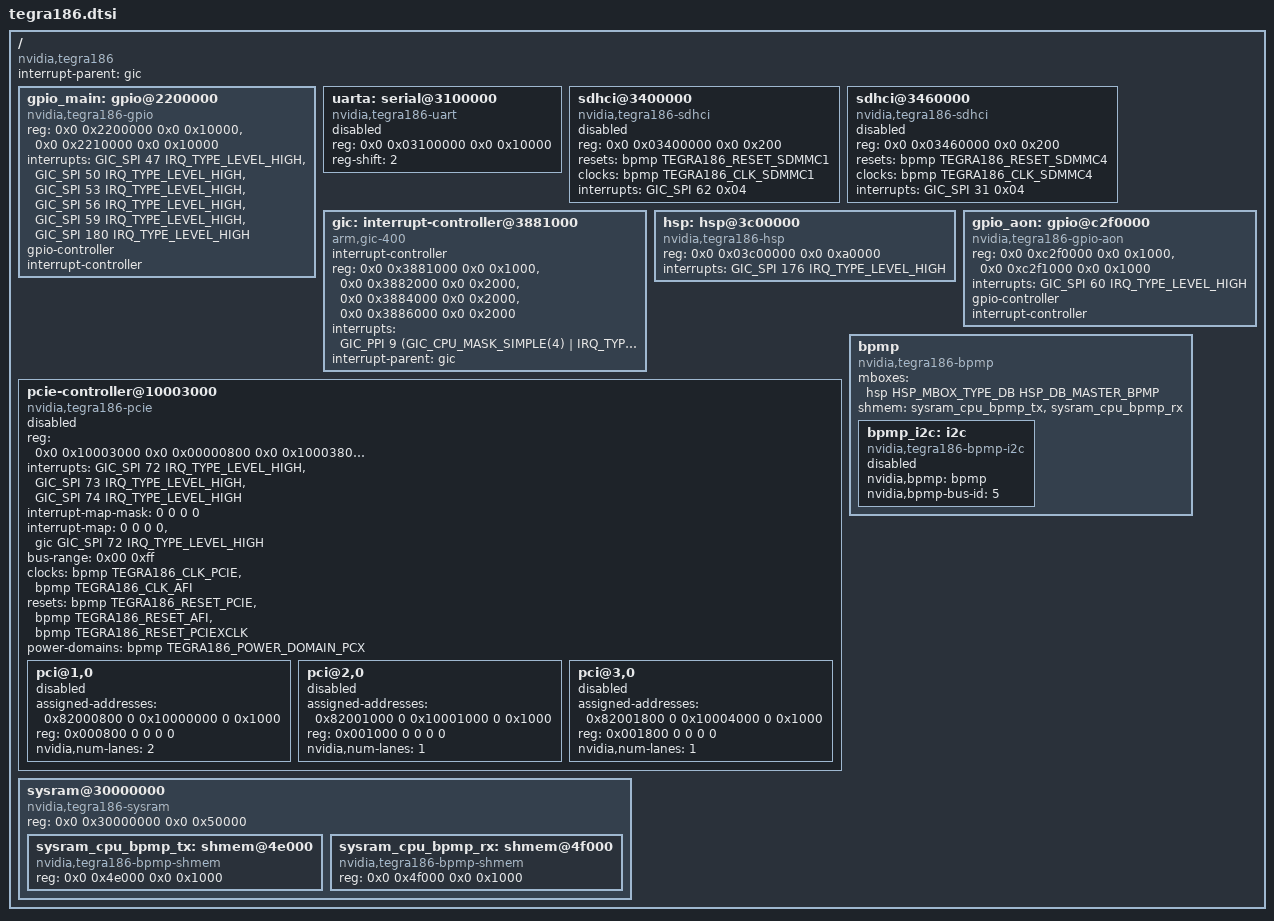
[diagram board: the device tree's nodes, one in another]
#include "skeleton.dtsi"
#include <dt-bindings/clock/tegra186-clock.h>
#include <dt-bindings/gpio/tegra186-gpio.h>
#include <dt-bindings/interrupt-controller/arm-gic.h>
#include <dt-bindings/mailbox/tegra186-hsp.h>
#include <dt-bindings/power/tegra186-powergate.h>
#include <dt-bindings/reset/tegra186-reset.h>

/ {
	compatible = "nvidia,tegra186";
	interrupt-parent = <&gic>;
	#address-cells = <2>;
	#size-cells = <2>;

	gpio_main: gpio@2200000 {
		compatible = "nvidia,tegra186-gpio";
		reg-names = "security", "gpio";
		reg =
			<0x0 0x2200000 0x0 0x10000>,
			<0x0 0x2210000 0x0 0x10000>;
		interrupts =
			<GIC_SPI 47 IRQ_TYPE_LEVEL_HIGH>,
			<GIC_SPI 50 IRQ_TYPE_LEVEL_HIGH>,
			<GIC_SPI 53 IRQ_TYPE_LEVEL_HIGH>,
			<GIC_SPI 56 IRQ_TYPE_LEVEL_HIGH>,
			<GIC_SPI 59 IRQ_TYPE_LEVEL_HIGH>,
			<GIC_SPI 180 IRQ_TYPE_LEVEL_HIGH>;
		gpio-controller;
		#gpio-cells = <2>;
		interrupt-controller;
		#interrupt-cells = <2>;
	};

	uarta: serial@3100000 {
		compatible = "nvidia,tegra186-uart", "nvidia,tegra20-uart";
		reg = <0x0 0x03100000 0x0 0x10000>;
		reg-shift = <2>;
		status = "disabled";
	};

	sdhci@3400000 {
		compatible = "nvidia,tegra186-sdhci";
		reg = <0x0 0x03400000 0x0 0x200>;
		resets = <&bpmp TEGRA186_RESET_SDMMC1>;
		reset-names = "sdmmc";
		clocks = <&bpmp TEGRA186_CLK_SDMMC1>;
		clock-names = "sdmmc";
		interrupts = <GIC_SPI 62 0x04>;
		status = "disabled";
	};

	sdhci@3460000 {
		compatible = "nvidia,tegra186-sdhci";
		reg = <0x0 0x03460000 0x0 0x200>;
		resets = <&bpmp TEGRA186_RESET_SDMMC4>;
		reset-names = "sdmmc";
		clocks = <&bpmp TEGRA186_CLK_SDMMC4>;
		clock-names = "sdmmc";
		interrupts = <GIC_SPI 31 0x04>;
		status = "disabled";
	};

	gic: interrupt-controller@3881000 {
		compatible = "arm,gic-400";
		#interrupt-cells = <3>;
		interrupt-controller;
		reg = <0x0 0x3881000 0x0 0x1000>,
		      <0x0 0x3882000 0x0 0x2000>,
		      <0x0 0x3884000 0x0 0x2000>,
		      <0x0 0x3886000 0x0 0x2000>;
		interrupts = <GIC_PPI 9
			(GIC_CPU_MASK_SIMPLE(4) | IRQ_TYPE_LEVEL_HIGH)>;
		interrupt-parent = <&gic>;
	};

	hsp: hsp@3c00000 {
		compatible = "nvidia,tegra186-hsp";
		reg = <0x0 0x03c00000 0x0 0xa0000>;
		interrupts = <GIC_SPI 176 IRQ_TYPE_LEVEL_HIGH>;
		interrupt-names = "doorbell";
		#mbox-cells = <2>;
	};

	gpio_aon: gpio@c2f0000 {
		compatible = "nvidia,tegra186-gpio-aon";
		reg-names = "security", "gpio";
		reg =
			<0x0 0xc2f0000 0x0 0x1000>,
			<0x0 0xc2f1000 0x0 0x1000>;
		interrupts =
			<GIC_SPI 60 IRQ_TYPE_LEVEL_HIGH>;
		gpio-controller;
		#gpio-cells = <2>;
		interrupt-controller;
		#interrupt-cells = <2>;
	};

	pcie-controller@10003000 {
		compatible = "nvidia,tegra186-pcie";
		device_type = "pci";
		reg = <0x0 0x10003000 0x0 0x00000800   /* PADS registers */
		       0x0 0x10003800 0x0 0x00000800   /* AFI registers */
		       0x0 0x40000000 0x0 0x10000000>; /* configuration space */
		reg-names = "pads", "afi", "cs";
		interrupts = <GIC_SPI 72 IRQ_TYPE_LEVEL_HIGH>, /* controller interrupt */
			     <GIC_SPI 73 IRQ_TYPE_LEVEL_HIGH>, /* MSI interrupt */
			     <GIC_SPI 74 IRQ_TYPE_LEVEL_HIGH>; /* Wake interrupt */
		interrupt-names = "intr", "msi", "wake";

		#interrupt-cells = <1>;
		interrupt-map-mask = <0 0 0 0>;
		interrupt-map = <0 0 0 0 &gic GIC_SPI 72 IRQ_TYPE_LEVEL_HIGH>;

		bus-range = <0x00 0xff>;
		#address-cells = <3>;
		#size-cells = <2>;

		ranges = <0x82000000 0 0x10000000 0x0 0x10000000 0 0x00001000   /* port 0 configuration space */
			  0x82000000 0 0x10001000 0x0 0x10001000 0 0x00001000   /* port 1 configuration space */
			  0x82000000 0 0x10004000 0x0 0x10004000 0 0x00001000   /* port 2 configuration space */
			  0x81000000 0 0x0        0x0 0x50000000 0 0x00010000   /* downstream I/O (64 KiB) */
			  0x82000000 0 0x50100000 0x0 0x50100000 0 0x07f00000   /* non-prefetchable memory (127 MiB) */
			  0xc2000000 0 0x58000000 0x0 0x58000000 0 0x28000000>; /* prefetchable memory (640 MiB) */

		clocks = <&bpmp TEGRA186_CLK_PCIE>,
			 <&bpmp TEGRA186_CLK_AFI>;
		clock-names = "pex", "afi";
		resets = <&bpmp TEGRA186_RESET_PCIE>,
			 <&bpmp TEGRA186_RESET_AFI>,
			 <&bpmp TEGRA186_RESET_PCIEXCLK>;
		reset-names = "pex", "afi", "pcie_x";
		power-domains = <&bpmp TEGRA186_POWER_DOMAIN_PCX>;
		status = "disabled";

		pci@1,0 {
			device_type = "pci";
			assigned-addresses = <0x82000800 0 0x10000000 0 0x1000>;
			reg = <0x000800 0 0 0 0>;
			status = "disabled";

			#address-cells = <3>;
			#size-cells = <2>;
			ranges;

			nvidia,num-lanes = <2>;
		};

		pci@2,0 {
			device_type = "pci";
			assigned-addresses = <0x82001000 0 0x10001000 0 0x1000>;
			reg = <0x001000 0 0 0 0>;
			status = "disabled";

			#address-cells = <3>;
			#size-cells = <2>;
			ranges;

			nvidia,num-lanes = <1>;
		};

		pci@3,0 {
			device_type = "pci";
			assigned-addresses = <0x82001800 0 0x10004000 0 0x1000>;
			reg = <0x001800 0 0 0 0>;
			status = "disabled";

			#address-cells = <3>;
			#size-cells = <2>;
			ranges;

			nvidia,num-lanes = <1>;
		};
	};

	sysram@30000000 {
		compatible = "nvidia,tegra186-sysram", "mmio-sram";
		reg = <0x0 0x30000000 0x0 0x50000>;
		#address-cells = <2>;
		#size-cells = <2>;
		ranges = <0 0x0 0x0 0x30000000 0x0 0x50000>;

		sysram_cpu_bpmp_tx: shmem@4e000 {
			compatible = "nvidia,tegra186-bpmp-shmem";
			reg = <0x0 0x4e000 0x0 0x1000>;
		};

		sysram_cpu_bpmp_rx: shmem@4f000 {
			compatible = "nvidia,tegra186-bpmp-shmem";
			reg = <0x0 0x4f000 0x0 0x1000>;
		};
	};

	bpmp: bpmp {
		compatible = "nvidia,tegra186-bpmp";
		mboxes = <&hsp HSP_MBOX_TYPE_DB HSP_DB_MASTER_BPMP>;
		/*
		 * In theory, these references, and the configuration in the
		 * node these reference point at, are board-specific, since
		 * they depend on the BCT's memory carve-out setup, the
		 * firmware that's actually loaded onto the BPMP, etc. However,
		 * in practice, all boards are likely to use identical values.
		 */
		shmem = <&sysram_cpu_bpmp_tx &sysram_cpu_bpmp_rx>;
		#clock-cells = <1>;
		#power-domain-cells = <1>;
		#reset-cells = <1>;

		bpmp_i2c: i2c {
			compatible = "nvidia,tegra186-bpmp-i2c";
			nvidia,bpmp = <&bpmp>;
			nvidia,bpmp-bus-id = <5>;
			#address-cells = <1>;
			#size-cells = <0>;
			status = "disabled";
		};
	};
};
